# npcx9m6f register map
Registers are 8-bit, read-write, no defined reset value unless marked. A register's access mark holds for its fields unless they carry their own. Offsets are from the block's base; [hi:lo] are bit positions; {n}, {i} and the like mark numbered series.

## ITIM32-1 — INTERNAL 32-BIT TIMER
Base 0x400B0000
Same registers: ITIM32-2 0x400B2000, ITIM32-3 0x400B4000, ITIM32-4 0x400B6000, ITIM32-5 0x400B8000, ITIM32-6 0x400BA000
0x00 ITCNT
0x01 ITPRE32n
0x02 ITCNT16 16-bit
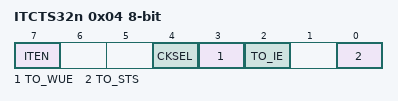
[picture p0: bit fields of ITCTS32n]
0x04 ITCTS32n
  [7] ITEN, [4] CKSEL, [3] TO_WUE, [2] TO_IE, [0] TO_STS
0x07 IT32VER
0x08 ITCNT32 32-bit

## MFT16-1 — MULTI-FUNCTION 16-BIT TIMER
Base 0x400E1000
Same registers: MFT16-2 0x400E3000, MFT16-3 0x400E5000, MFT16-4 0x400E7000, MFT16-5 0x400E9000
0x00 TnCNT1 16-bit
0x02 TnCRA 16-bit
0x04 TnCRB 16-bit
0x06 TnCNT2 16-bit
0x08 TnPRSC
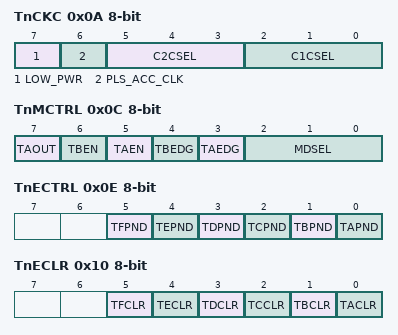
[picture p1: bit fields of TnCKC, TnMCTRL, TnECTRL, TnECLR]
0x0A TnCKC
  [7] LOW_PWR, [6] PLS_ACC_CLK, [5:3] C2CSEL, [2:0] C1CSEL
0x0C TnMCTRL
  [7] TAOUT, [6] TBEN, [5] TAEN, [4] TBEDG, [3] TAEDG, [2:0] MDSEL
0x0E TnECTRL
  [5] TFPND, [4] TEPND, [3] TDPND, [2] TCPND, [1] TBPND, [0] TAPND
0x10 TnECLR
  [5] TFCLR, [4] TECLR, [3] TDCLR, [2] TCCLR, [1] TBCLR, [0] TACLR
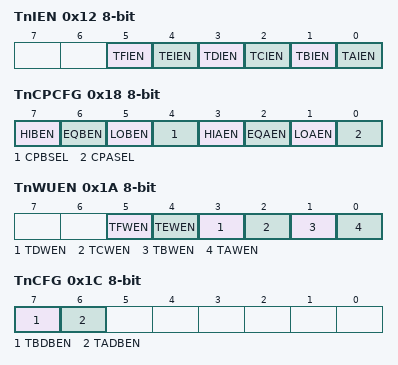
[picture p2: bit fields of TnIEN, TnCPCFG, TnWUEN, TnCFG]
0x12 TnIEN
  [5] TFIEN, [4] TEIEN, [3] TDIEN, [2] TCIEN, [1] TBIEN, [0] TAIEN
0x14 TnCPA 16-bit
0x16 TnCPB 16-bit
0x18 TnCPCFG
  [7] HIBEN, [6] EQBEN, [5] LOBEN, [4] CPBSEL, [3] HIAEN, [2] EQAEN, [1] LOAEN, [0] CPASEL
0x1A TnWUEN
  [5] TFWEN, [4] TEWEN, [3] TDWEN, [2] TCWEN, [1] TBWEN, [0] TAWEN
0x1C TnCFG
  [7] TBDBEN, [6] TADBEN
0x1E MFTnVER

## OWI — OWI Module
Base 0x400EB000
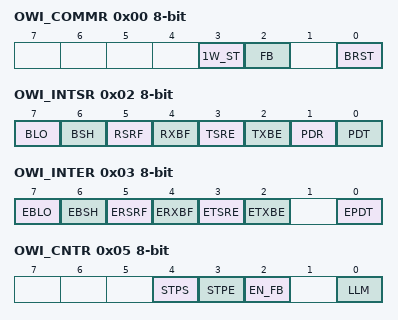
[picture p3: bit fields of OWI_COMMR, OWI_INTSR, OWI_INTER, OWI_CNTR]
0x00 OWI_COMMR
  [3] 1W_ST, [2] FB, [0] BRST
0x01 OWI_RXB
0x01 OWI_TXB
0x02 OWI_INTSR
  [7] BLO, [6] BSH, [5] RSRF, [4] RXBF, [3] TSRE, [2] TXBE, [1] PDR, [0] PDT
0x03 OWI_INTER
  [7] EBLO, [6] EBSH, [5] ERSRF, [4] ERXBF, [3] ETSRE, [2] ETXBE, [0] EPDT
0x04 OWI_CKDVR
0x05 OWI_CNTR
  [4] STPS, [3] STPE, [2] EN_FB, [0] LLM
0x07 OWI_VER

## ADC — ADC Module
Base 0x400D1000
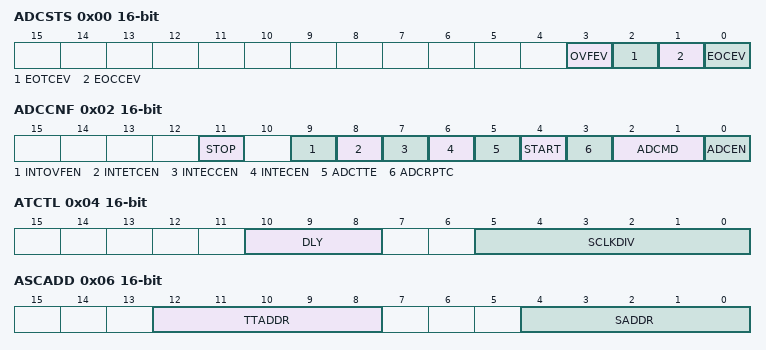
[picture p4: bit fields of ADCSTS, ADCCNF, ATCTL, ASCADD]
0x00 ADCSTS 16-bit
  [3] OVFEV, [2] EOTCEV, [1] EOCCEV, [0] EOCEV
0x02 ADCCNF 16-bit
  [11] STOP, [9] INTOVFEN, [8] INTETCEN, [7] INTECCEN, [6] INTECEN, [5] ADCTTE, [4] START, [3] ADCRPTC, [2:1] ADCMD, [0] ADCEN
0x04 ATCTL 16-bit
  [10:8] DLY, [5:0] SCLKDIV
0x06 ASCADD 16-bit
  [12:8] TTADDR, [4:0] SADDR
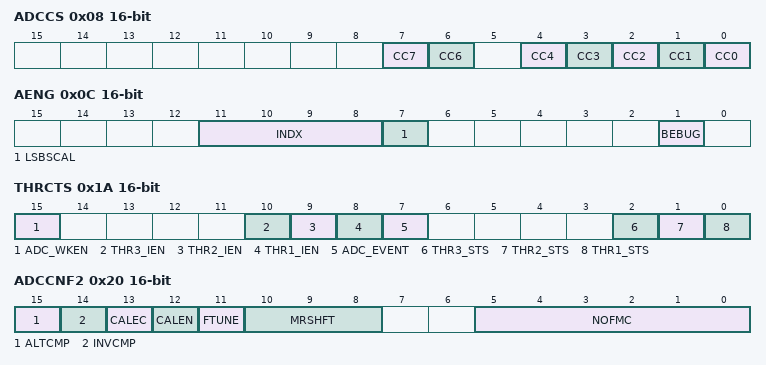
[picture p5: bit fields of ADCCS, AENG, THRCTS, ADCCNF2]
0x08 ADCCS 16-bit
  [7] CC7, [6] CC6, [n] CC{n} (n=0..4)
0x0C AENG 16-bit
  [11:8] INDX, [7] LSBSCAL, [1] BEBUG
0x12 AENG_DATA 16-bit
{0x12+2i} THRCTL{i} 16-bit (i=1..3)
  [15] THEN, [14] L_H, [13:10] CHNSEL, [9:2] THRVAL8, [9:2] THRVAL, [9:0] THRVAL10, [9:0] THRVAL
0x1A THRCTS 16-bit
  [15] ADC_WKEN, [10] THR3_IEN, [9] THR2_IEN, [8] THR1_IEN, [7] ADC_EVENT, [2] THR3_STS, [1] THR2_STS, [0] THR1_STS
0x20 ADCCNF2 16-bit
  [15] ALTCMP, [14] INVCMP, [13] CALEC, [12] CALEN, [11] FTUNE, [10:8] MRSHFT, [5:0] NOFMC
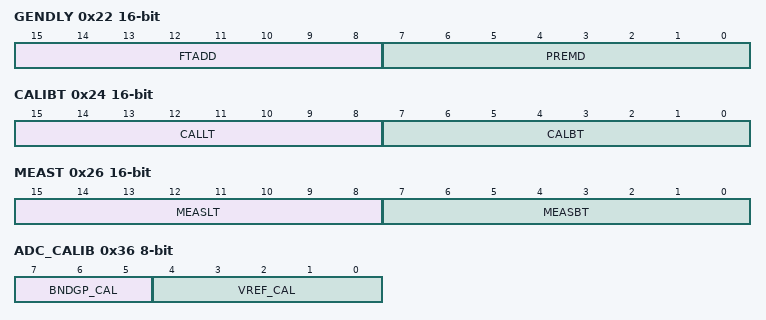
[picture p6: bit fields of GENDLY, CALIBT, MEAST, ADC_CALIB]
0x22 GENDLY 16-bit
  [15:8] FTADD, [7:0] PREMD
0x24 CALIBT 16-bit
  [15:8] CALLT, [7:0] CALBT
0x26 MEAST 16-bit
  [15:8] MEASLT, [7:0] MEASBT
0x36 ADC_CALIB
  [7:5] BNDGP_CAL, [4:0] VREF_CAL
0x38 ADC_MISC_CFG
  [1:0] RC_SEL
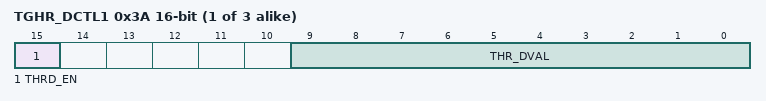
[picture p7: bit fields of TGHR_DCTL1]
{0x38+2i} TGHR_DCTL{i} 16-bit (i=1..3)
  [15] THRD_EN, [9:0] THR_DVAL
{0x40+2i} CHN{i}DAT 16-bit (i=0..4)
  [15] NEW, [9:2] CHDAT8, [9:2] CHDAT, [9:0] CHDAT10, [9:0] CHDAT
{0x40+2i} CHN{i}DAT 16-bit (i=6..11)
  [15] NEW, [9:2] CHDAT8, [9:2] CHDAT, [9:0] CHDAT10, [9:0] CHDAT

## DAC — DAC Module
Base 0x400D3000
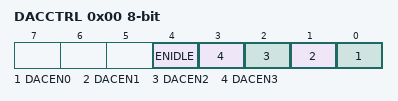
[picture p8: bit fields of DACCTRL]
0x00 DACCTRL
  [4] ENIDLE, [n] DACEN{n} (n=0..3)
{0x2+2i} DACDAT{i} (i=0..3)
0x0E DAC_VER

## DSADC
Base 0x400D1100
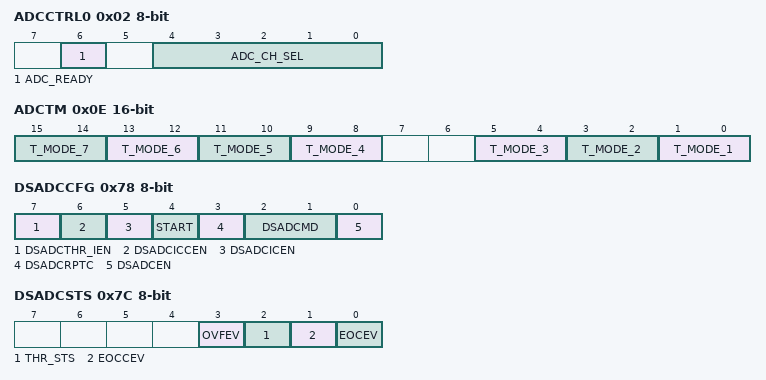
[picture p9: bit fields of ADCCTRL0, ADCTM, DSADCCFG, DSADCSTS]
0x02 ADCCTRL0
  [6] ADC_READY, [4:0] ADC_CH_SEL
0x04 ADCCTRL1
  [6:0] ADC_CLK_SEL
0x0E ADCTM 16-bit
  [2n+1:2n] T_MODE_{n} (n=4..7), [5:4] T_MODE_3, [3:2] T_MODE_2, [1:0] T_MODE_1
0x76 ANAD2 16-bit
  [8:0] ANAD2
0x78 DSADCCFG
  [7] DSADCTHR_IEN, [6] DSADCICCEN, [5] DSADCICEN, [4] START, [3] DSADCRPTC, [2:1] DSADCMD, [0] DSADCEN
0x7A DSADCCS
  [6:0] CC6-0
0x7C DSADCSTS
  [3] OVFEV, [2] THR_STS, [1] EOCCEV, [0] EOCEV
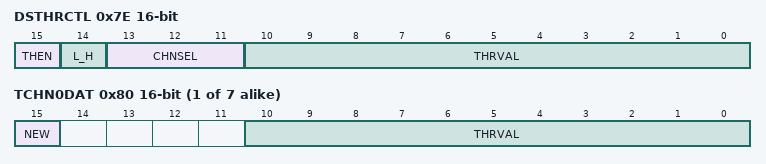
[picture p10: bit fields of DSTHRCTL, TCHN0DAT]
0x7E DSTHRCTL 16-bit
  [15] THEN, [14] L_H, [13:11] CHNSEL, [10:0] THRVAL
{0x80+2i} TCHN{i}DAT 16-bit (i=0..6)
  [15] NEW, [10:0] THRVAL
